AUTOSAR XML (schema 00044)
package /COM/VECTOR/CFG/WORKFLOW/SYSDESC/SYNC
  system SYSTEM: category=ECU_EXTRACT
    system mapping MAPPINGS
    root-software-compositions:
      root sw composition prototype COMPOSITIONTYPE: flat-map=FLATMAP, software-composition=COMPOSITIONTYPE
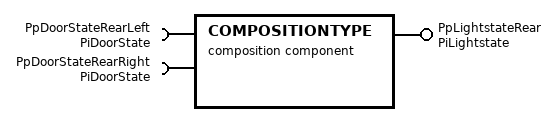
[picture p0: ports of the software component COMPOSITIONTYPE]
  composition sw component type COMPOSITIONTYPE  # UB:Derived from original system description
    require port PpDoorStateRearLeft: nonqueued-receiver-com-spec{data-element=DeDoorState, init-value=0}, required-interface=PiDoorState
    require port PpDoorStateRearRight: nonqueued-receiver-com-spec{data-element=DeDoorState, init-value=0}, required-interface=PiDoorState
    provide port PpLightstateRear: nonqueued-sender-com-spec{data-element=DeLightstate, init-value=0}, provided-interface=PiLightstate
    10 x component:
      CpApMySwc: type=CtApMySwc
      CpSaDoorFrontLeft: type=CtSaDoor
      CpSalnteriorLight: type=CtSalnteriorLight
      CpSaDoorFrontRight: type=CtSaDoor
      BswM: type=BswM
      ComM: type=ComM
      Det: type=Det
      EcuM: type=EcuM
      CtCddloHwAb: type=CtCddloHwAb
      NvM: type=NvM
    connect CpApMySwc.PpLightStateFront -> CpSalnteriorLight.PpLightstate  # UB:Derived from original system description
    connect CpSaDoorFrontLeft.PpDoorState -> CpApMySwc.PpDoorStateFrontLeft  # UB:Derived from original system description
    connect CpSaDoorFrontRight.PpDoorState -> CpApMySwc.PpDoorStateFrontRight  # UB:Derived from original system description
    delegate CpApMySwc.PpLightstateRear <-> outer port PpLightstateRear  # UB:Derived from original system description
    delegate CpApMySwc.PpDoorStateRearLeft <-> outer port PpDoorStateRearLeft  # UB:Derived from original system description
    delegate CpApMySwc.PpDoorStateRearRight <-> outer port PpDoorStateRearRight  # UB:Derived from original system description
    connect CtCddloHwAb.PpInteriorLightFront -> CpSalnteriorLight.PpInteriorLightloHwAb  # UB:Derived from original system description
    connect CtCddloHwAb.PpDoorFrontLeft -> CpSaDoorFrontLeft.PpDoorloHwAb  # UB:Derived from original system description
    connect CtCddloHwAb.PpDoorFrontRight -> CpSaDoorFrontRight.PpDoorloHwAb  # UB:Derived from original system description
    connect ComM.UR_CN_CAN00_aa6f78c5 -> CpApMySwc.PpComMUserRequest
    connect BswM.Switch_ESH_ModeSwitch -> BswM.Notification_ESH_ModeNotification
    connect NvM.PS_CpApMySwcSnNvMPimLightOnOffCounter -> CpApMySwc.PpNvMLightOnOffCtApMySwc
    connect CpApMySwc.PpNvMNotifyJobFinishedOdometerCtApMySwc -> NvM.NvM_RpNotifyJobEnd_CpApMySwcSnNvMPimOdometer
    connect NvM.PS_CpApMySwcSnNvMPimOdometer -> CpApMySwc.PpNvMOdometerCtApMyswc
  end to end protection set E2EPROTECTIONSET
  port interface mapping set PORTINTERFACEMAPPINGSET
